# RL7005_IP_SVD register map
Vendor: Realtek
Registers are 32-bit, read-write, reset 0x0 unless marked. A register's access mark holds for its fields unless they carry their own. Offsets are from the block's base; [hi:lo] are bit positions; {n}, {i} and the like mark numbered series.

## PAGE1 (part 2 of 2)
Base 0x40000000
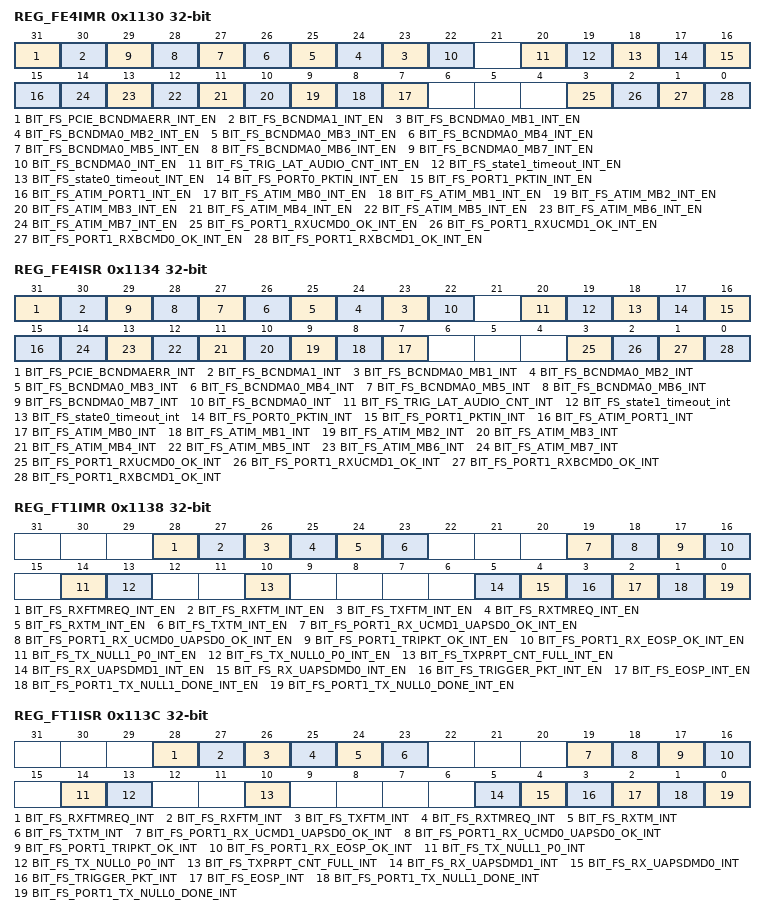
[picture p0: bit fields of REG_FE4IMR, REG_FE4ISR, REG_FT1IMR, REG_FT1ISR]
0x1130 REG_FE4IMR
  [31] BIT_FS_PCIE_BCNDMAERR_INT_EN — PCIE BCN DMA error interrupt
  [30] BIT_FS_BCNDMA1_INT_EN — When BCNDMA interval arrives before TBTT1, this interrupt informs MCU to prepare related beacon tasks.
  [n+22] BIT_FS_BCNDMA0_MB{n}_INT_EN (n=1..7) — When BCNDMA interval arrives before TBTT0_MB{n}, this interrupt informs MCU to prepare related beacon tasks.
  [22] BIT_FS_BCNDMA0_INT_EN — When BCNDMA interval arrives before TBTT0_MB0, this interrupt informs MCU to prepare related beacon tasks.
  [20] BIT_FS_TRIG_LAT_AUDIO_CNT_INT_EN — WLMAC trigger audio to latch counter periodically. Generate by P0/P1's TSFT.
  [19] BIT_FS_state1_timeout_INT_EN — when state0_timeout_timer is equal to r_state0_timeout_thres, which means state_0 is hang, hw will set this interrupt to inform sw
  [18] BIT_FS_state0_timeout_INT_EN — when state0_timeout_timer is equal to r_state0_timeout_thres, which means state_0 is hang, hw will set this interrupt to inform sw
  [17] BIT_FS_PORT0_PKTIN_INT_EN — port 0 packet assign to queue interrupt
  [16] BIT_FS_PORT1_PKTIN_INT_EN — port 1 packet assign to queue interrupt
  [15] BIT_FS_ATIM_PORT1_INT_EN — PORT1 ATIM end window interrupt .
  [n+7] BIT_FS_ATIM_MB{n}_INT_EN (n=0..7) — MBSSID{n} ATIM end window interrupt .
  [3] BIT_FS_PORT1_RXUCMD0_OK_INT_EN — port 1 rx unicast packet with more data = 0 ok interrupt
  [2] BIT_FS_PORT1_RXUCMD1_OK_INT_EN — port 1 rx unicast packet with more data = 1 ok interrupt
  [1] BIT_FS_PORT1_RXBCMD0_OK_INT_EN — port 1 rx broadcast packet with more data = 0 ok interrupt
  [0] BIT_FS_PORT1_RXBCMD1_OK_INT_EN — port 1 rx broadcast packet with more data = 1 ok interrupt
0x1134 REG_FE4ISR ro
  [31] BIT_FS_PCIE_BCNDMAERR_INT — PCIE BCN DMA error interrupt
  [30] BIT_FS_BCNDMA1_INT — When BCNDMA interval arrives before TBTT1, this interrupt informs MCU to prepare related beacon tasks.
  [n+22] BIT_FS_BCNDMA0_MB{n}_INT (n=1..7) — When BCNDMA interval arrives before TBTT0_MB{n}, this interrupt informs MCU to prepare related beacon tasks.
  [22] BIT_FS_BCNDMA0_INT — When BCNDMA interval arrives before TBTT0_MB0, this interrupt informs MCU to prepare related beacon tasks.
  [20] BIT_FS_TRIG_LAT_AUDIO_CNT_INT — WLMAC trigger audio to latch counter periodically. Generate by P0/P1's TSFT.
  [19] BIT_FS_state1_timeout_int — when state0_timeout_timer is equal to r_state0_timeout_thres, which means state_0 is hang, hw will set this interrupt to inform sw
  [18] BIT_FS_state0_timeout_int — when state0_timeout_timer is equal to r_state0_timeout_thres, which means state_0 is hang, hw will set this interrupt to inform sw
  [17] BIT_FS_PORT0_PKTIN_INT — port 0 packet assign to queue interrupt
  [16] BIT_FS_PORT1_PKTIN_INT — port 1 packet assign to queue interrupt
  [15] BIT_FS_ATIM_PORT1_INT — PORT1 ATIM end window interrupt .
  [n+7] BIT_FS_ATIM_MB{n}_INT (n=0..7) — MBSSID{n} ATIM end window interrupt .
  [3] BIT_FS_PORT1_RXUCMD0_OK_INT — port 1 rx unicast packet with more data = 0 ok interrupt
  [2] BIT_FS_PORT1_RXUCMD1_OK_INT — port 1 rx unicast packet with more data = 1 ok interrupt
  [1] BIT_FS_PORT1_RXBCMD0_OK_INT — port 1 rx broadcast packet with more data = 0 ok interrupt
  [0] BIT_FS_PORT1_RXBCMD1_OK_INT — port 1 rx broadcast packet with more data = 1 ok interrupt
0x1138 REG_FT1IMR
  [28] BIT_FS_RXFTMREQ_INT_EN — If BIT_RXFTMREQ_INT_EN =1. When HW receive FTMREQ packet, it will generate interrupt to firmware.
  [27] BIT_FS_RXFTM_INT_EN — If BIT_RXFTM_INT_EN =1. When HW receive FTM and transmit ACK frame successfully, the BB generate FTM report. It will generate interrupt to firmware.
  [26] BIT_FS_TXFTM_INT_EN — If BIT_TXFTM_INT_EN =1. When HW transmit FTM and receive ACK frame successfully, the BB generate FTM report. It will generate interrupt to firmware.
  [25] BIT_FS_RXTMREQ_INT_EN — If BIT_RXTMREQ_INT_EN =1. When HW receive TMREQ packet, it will generate interrupt to firmware.
  [24] BIT_FS_RXTM_INT_EN — If BIT_RXTM_INT_EN =1. When HW receive TM and transmit ACK frame successfully. It will generate interrupt to firmware.
  [23] BIT_FS_TXTM_INT_EN — If BIT_TXTM_INT_EN =1. When HW transmit TM and receive ACK frame successfully. It will generate interrupt to firmware.
  [19] BIT_FS_PORT1_RX_UCMD1_UAPSD0_OK_INT_EN — PORT1 rx unicast packet ok interrupt with more data =1 & UAPSD =0
  [18] BIT_FS_PORT1_RX_UCMD0_UAPSD0_OK_INT_EN — PORT1 rx unicast packet ok interrupt with more data =0 & UAPSD =0
  [17] BIT_FS_PORT1_TRIPKT_OK_INT_EN — PORT1 trigger packet assign to queue or release interrupt
  [16] BIT_FS_PORT1_RX_EOSP_OK_INT_EN — PORT1 RX packet with EOSP =1 ok interrupt
  [14] BIT_FS_TX_NULL1_P0_INT_EN — TX null 1 packet done interrupt
  [13] BIT_FS_TX_NULL0_P0_INT_EN — TX null 0 packet done interrupt
  [10] BIT_FS_TXPRPT_CNT_FULL_INT_EN — txrpt buffer full interrupt
  [5] BIT_FS_RX_UAPSDMD1_INT_EN — Setting this bit indicates Rx pkt is matched with one of below: 1.) QoS Unicast data frame with MD=1, UAPSD=0 2.) NonQoS Unicast data frame with MD=1
  [4] BIT_FS_RX_UAPSDMD0_INT_EN — Setting this bit indicates Rx pkt is matched with one of below: 1.) QoS Unicast data frame with MD=0, UAPSD=0 2.) NonQoS Unicast data frame with MD=0
  [3] BIT_FS_TRIGGER_PKT_INT_EN — tx TRIGGER_PKT interrupt
  [2] BIT_FS_EOSP_INT_EN — EOSP_INT interrupt mask
  [1] BIT_FS_PORT1_TX_NULL1_DONE_INT_EN — PORT1 TX NULL1 packet ok interrupt
  [0] BIT_FS_PORT1_TX_NULL0_DONE_INT_EN — PORT1 TX NULL0 packet ok interrupt
0x113C REG_FT1ISR ro
  [28] BIT_FS_RXFTMREQ_INT — If BIT_RXFTMREQ_INT_EN =1. When HW receive FTMREQ packet, it will generate interrupt to firmware.
  [27] BIT_FS_RXFTM_INT — If BIT_RXFTM_INT_EN =1. When HW receive FTM and transmit ACK frame successfully, the BB generate FTM report. It will generate interrupt to firmware.
  [26] BIT_FS_TXFTM_INT — If BIT_TXFTM_INT_EN =1. When HW transmit FTM and receive ACK frame successfully, the BB generate FTM report. It will generate interrupt to firmware.
  [25] BIT_FS_RXTMREQ_INT — If BIT_RXTMREQ_INT_EN =1. When HW receive TMREQ packet, it will generate interrupt to firmware.
  [24] BIT_FS_RXTM_INT — If BIT_RXTM_INT_EN =1. When HW receive TM and transmit ACK frame successfully. It will generate interrupt to firmware.
  [23] BIT_FS_TXTM_INT — If BIT_TXTM_INT_EN =1. When HW transmit TM and receive ACK frame successfully. It will generate interrupt to firmware.
  [19] BIT_FS_PORT1_RX_UCMD1_UAPSD0_OK_INT — PORT1 rx unicast packet ok interrupt with more data =1 & UAPSD =0
  [18] BIT_FS_PORT1_RX_UCMD0_UAPSD0_OK_INT — PORT1 rx unicast packet ok interrupt with more data =0 & UAPSD =0
  [17] BIT_FS_PORT1_TRIPKT_OK_INT — PORT1 trigger packet assign to queue or release interrupt
  [16] BIT_FS_PORT1_RX_EOSP_OK_INT — PORT1 RX packet with EOSP =1 ok interrupt
  [14] BIT_FS_TX_NULL1_P0_INT — TX null 1 packet done interrupt
  [13] BIT_FS_TX_NULL0_P0_INT — TX null 0 packet done interrupt
  [10] BIT_FS_TXPRPT_CNT_FULL_INT — txrpt buffer full interrupt
  [5] BIT_FS_RX_UAPSDMD1_INT — Setting this bit indicates Rx pkt is matched with one of below: 1.) QoS Unicast data frame with MD=1, UAPSD=0 2.) NonQoS Unicast data frame with MD=1
  [4] BIT_FS_RX_UAPSDMD0_INT — Setting this bit indicates Rx pkt is matched with one of below: 1.) QoS Unicast data frame with MD=0, UAPSD=0 2.) NonQoS Unicast data frame with MD=0
  [3] BIT_FS_TRIGGER_PKT_INT — tx TRIGGER_PKT interrupt
  [2] BIT_FS_EOSP_INT — EOSP_INT interrupt mask
  [1] BIT_FS_PORT1_TX_NULL1_DONE_INT — PORT1 TX NULL1 packet ok interrupt
  [0] BIT_FS_PORT1_TX_NULL0_DONE_INT — PORT1 TX NULL0 packet ok interrupt
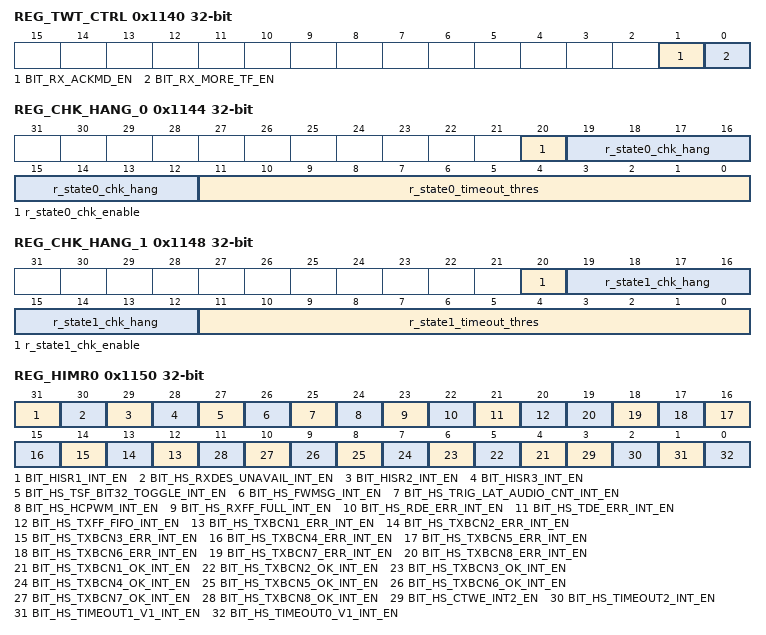
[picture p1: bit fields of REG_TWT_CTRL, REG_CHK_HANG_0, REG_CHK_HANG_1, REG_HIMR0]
0x1140 REG_TWT_CTRL
  [1] BIT_RX_ACKMD_EN — Enable ACK/BA/MU-BA frame more data interrupt
  [0] BIT_RX_MORE_TF_EN — Enable trigger frame more TF field interrupt
0x1144 REG_CHK_HANG_0
  [20] r_state0_chk_enable — function enable of check hang of state_0
  [19:12] r_state0_chk_hang — when r_state0_chk_enable is set, if state_0 is the value is equal to r_state0_chk_hang, starts state0_timeout_timer
  [11:0] r_state0_timeout_thres — timeout threshold of state0_timeout_timer, unit:us
0x1148 REG_CHK_HANG_1
  [20] r_state1_chk_enable — function enable of check hang of state_1
  [19:12] r_state1_chk_hang — when r_state1_chk_enable is set, if state_1 is the value is equal to r_state1_chk_hang, starts state1_timeout_timer
  [11:0] r_state1_timeout_thres — timeout threshold of state0_timeout_timer, unit:us
0x1150 REG_HIMR0
  [31] BIT_HISR1_INT_EN — HISR1 Indicator (HIISR1 andHIMR1 are true, this bit is set to 1)
  [30] BIT_HS_RXDES_UNAVAIL_INT_EN — Rx Descriptor Unavailable
  [29] BIT_HISR2_INT_EN — HISR2 Indicator (HIISR2 andHIMR2 are true, this bit is set to 1)
  [28] BIT_HISR3_INT_EN — HISR3 Indicator (HIISR3 andHIMR3 are true, this bit is set to 1)
  [27] BIT_HS_TSF_BIT32_TOGGLE_INT_EN — TSF Timer BIT32 toggle indication interrupt
  [26] BIT_HS_FWMSG_INT_EN — FW message interrupt,CPU to Host Command INT Status, Write 1 clear
  [25] BIT_HS_TRIG_LAT_AUDIO_CNT_INT_EN — WLMAC trigger audio to latch counter periodically. Generate by P0/P1's TSFT.
  [24] BIT_HS_HCPWM_INT_EN — CPWM interrupt,CPU power Mode exchange INT Status, Write 1 clear
  [23] BIT_HS_RXFF_FULL_INT_EN — Rxpktbuffer full interrupt
  [22] BIT_HS_RDE_ERR_INT_EN — Rxdma error interrupt
  [21] BIT_HS_TDE_ERR_INT_EN — Txdma error interrupt
  [20] BIT_HS_TXFF_FIFO_INT_EN — txpktbuffer full interrupt
  [n+11] BIT_HS_TXBCN{n}_ERR_INT_EN (n=1..8) — port0 BSSID{n-1} TX beacon error interrupt
  [n+3] BIT_HS_TXBCN{n}_OK_INT_EN (n=1..8) — port0 BSSID{n-1} TX beacon ok interrupt
  [3] BIT_HS_CTWE_INT2_EN — port2 CTWindow end interrupt for p2p.
  [2] BIT_HS_TIMEOUT2_INT_EN — tsf Timer2 interrupt
  [1] BIT_HS_TIMEOUT1_V1_INT_EN — tsf Timer1 interrupt
  [0] BIT_HS_TIMEOUT0_V1_INT_EN — tsf Timer0 interrupt
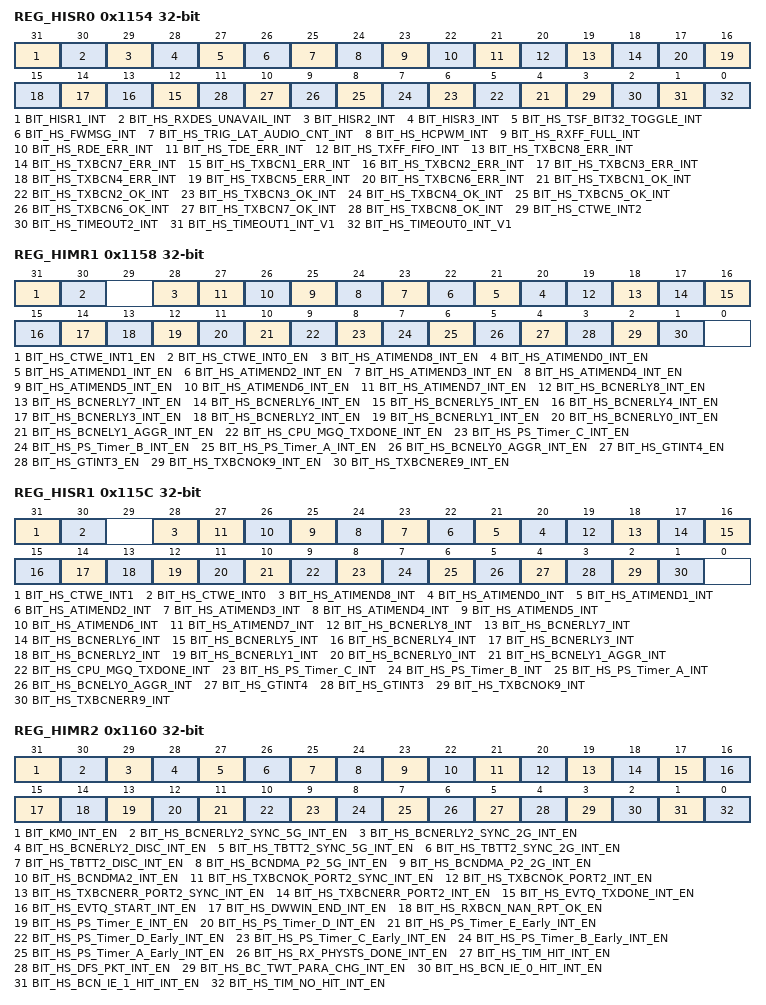
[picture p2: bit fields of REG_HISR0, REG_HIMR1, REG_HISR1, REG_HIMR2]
0x1154 REG_HISR0 ro
  [31] BIT_HISR1_INT — HISR1 Indicator (HIISR1 andHIMR1 are true, this bit is set to 1)
  [30] BIT_HS_RXDES_UNAVAIL_INT — Rx Descriptor Unavailable
  [29] BIT_HISR2_INT — HISR2 Indicator (HIISR2 andHIMR2 are true, this bit is set to 1)
  [28] BIT_HISR3_INT — HISR3 Indicator (HIISR3 andHIMR3 are true, this bit is set to 1)
  [27] BIT_HS_TSF_BIT32_TOGGLE_INT — TSF Timer BIT32 toggle indication interrupt
  [26] BIT_HS_FWMSG_INT — FW message interrupt,CPU to Host Command INT Status, Write 1 clear
  [25] BIT_HS_TRIG_LAT_AUDIO_CNT_INT — WLMAC trigger audio to latch counter periodically. Generate by P0/P1's TSFT.
  [24] BIT_HS_HCPWM_INT — CPWM interrupt,CPU power Mode exchange INT Status, Write 1 clear
  [23] BIT_HS_RXFF_FULL_INT — Rxpktbuffer full interrupt
  [22] BIT_HS_RDE_ERR_INT — Rxdma error interrupt
  [21] BIT_HS_TDE_ERR_INT — Txdma error interrupt
  [20] BIT_HS_TXFF_FIFO_INT — txpktbuffer full interrupt
  [19] BIT_HS_TXBCN8_ERR_INT — port0 BSSID7 TRX beacon error interrupt (ap is txbcn, sta is rxbcn)
  [18] BIT_HS_TXBCN7_ERR_INT — port0 BSSID6 TRX beacon error interrupt (ap is txbcn, sta is rxbcn)
  [n+11] BIT_HS_TXBCN{n}_ERR_INT (n=1..6) — port0 BSSID{n-1} TRX beacon error interrupt(ap is txbcn, sta is rxbcn)
  [n+3] BIT_HS_TXBCN{n}_OK_INT (n=1..8) — port0 BSSID{n-1} TRX beacon ok interrupt(ap is txbcn, sta is rxbcn)
  [3] BIT_HS_CTWE_INT2 — port2 CTWindow end interrupt for p2p.
  [2] BIT_HS_TIMEOUT2_INT — tsf Timer2 interrupt
  [1] BIT_HS_TIMEOUT1_INT_V1 — tsf Timer1 interrupt
  [0] BIT_HS_TIMEOUT0_INT_V1 — tsf Timer0 interrupt
0x1158 REG_HIMR1
  [31] BIT_HS_CTWE_INT1_EN — Client1 traffic window end interrupt for P2P
  [30] BIT_HS_CTWE_INT0_EN — Client0 traffic window end interrupt for P2P
  [28] BIT_HS_ATIMEND8_INT_EN — port1 atimend interrupt
  [n+20] BIT_HS_ATIMEND{n}_INT_EN (n=0..7) — port0 BSSID{n} atimend interrupt
  [19] BIT_HS_BCNERLY8_INT_EN — port1 beacon early interrupt
  [18] BIT_HS_BCNERLY7_INT_EN — port0 BSSID7 beacon early interrupt , only valid under MBSSID mode
  [17] BIT_HS_BCNERLY6_INT_EN — port0 BSSID6 beacon early interrupt , only valid under MBSSID mode
  [16] BIT_HS_BCNERLY5_INT_EN — port0 BSSID5 beacon early interrupt , only valid under MBSSID mode
  [15] BIT_HS_BCNERLY4_INT_EN — port0 BSSID4 beacon early interrupt, only valid under MBSSID mode
  [14] BIT_HS_BCNERLY3_INT_EN — port0 BSSID3 beacon early interrupt , only valid under MBSSID mode
  [13] BIT_HS_BCNERLY2_INT_EN — port0 BSSID2 beacon early interrupt, only valid under MBSSID mode
  [12] BIT_HS_BCNERLY1_INT_EN — port0 BSSID1 beacon early interrupt , only valid under MBSSID mode
  [11] BIT_HS_BCNERLY0_INT_EN — This interrupt is issued at the time set by DRVERLYINT register before TBTT time for port 0 root bssid
  [10] BIT_HS_BCNELY1_AGGR_INT_EN — port 1 Beacon early aggregation interrupt
  [9] BIT_HS_CPU_MGQ_TXDONE_INT_EN — CPU_MQG_TXDONE ineterrupt source when HW TX CPUMGQ packet success, it issue interrupt to host
  [8] BIT_HS_PS_Timer_C_INT_EN — PS_Timer_C interrupt source When the lower 4 bytes of TSF(that select by reg 0x1510[18:16]) matches the content of this register, the PS_Timer_C_INT interrupt is issued
  [7] BIT_HS_PS_Timer_B_INT_EN — PS_Timer_B interrupt source When the lower 4 bytes of TSF(that select by reg 0x1510[10:8]) matches the content of this register, the PS_Timer_B_INT interrupt is issued
  [6] BIT_HS_PS_Timer_A_INT_EN — PS_Timer_A interrupt source When the lower 4 bytes of TSF(that select by reg 0x1510[2:0]) matches the content of this register, the PS_Timer_A_INT interrupt is issued
  [5] BIT_HS_BCNELY0_AGGR_INT_EN — port 0 Beacon early aggregation interrupt
  [4] BIT_HS_GTINT4_EN — When GTIMER4 expires, this bit is set to 1
  [3] BIT_HS_GTINT3_EN — When GTIMER3 expires, this bit is set to 1
  [2] BIT_HS_TXBCNOK9_INT_EN — PORT1 TRX beacon OK interrupt (ap is txbcn, sta is rxbcn)
  [1] BIT_HS_TXBCNERE9_INT_EN — PORT1 TRX beacon Error interrupt (ap is txbcn, sta is rxbcn)
0x115C REG_HISR1 ro
  [31] BIT_HS_CTWE_INT1 — port1 CTWindow end interrupt for p2p.
  [30] BIT_HS_CTWE_INT0 — port0 CTWindow end interrupt for p2p.
  [28] BIT_HS_ATIMEND8_INT — port1 atimend interrupt
  [n+20] BIT_HS_ATIMEND{n}_INT (n=0..7) — port0 BSSID{n} atimend interrupt
  [19] BIT_HS_BCNERLY8_INT — port1 beacon early interrupt
  [18] BIT_HS_BCNERLY7_INT — port0 BSSID7 beacon early interrupt , only valid under MBSSID mode
  [17] BIT_HS_BCNERLY6_INT — port0 BSSID6 beacon early interrupt , only valid under MBSSID mode
  [16] BIT_HS_BCNERLY5_INT — port0 BSSID5 beacon early interrupt , only valid under MBSSID mode
  [15] BIT_HS_BCNERLY4_INT — port0 BSSID4 beacon early interrupt, only valid under MBSSID mode
  [14] BIT_HS_BCNERLY3_INT — port0 BSSID3 beacon early interrupt , only valid under MBSSID mode
  [13] BIT_HS_BCNERLY2_INT — port0 BSSID2 beacon early interrupt, only valid under MBSSID mode
  [12] BIT_HS_BCNERLY1_INT — port0 BSSID1 beacon early interrupt , only valid under MBSSID mode
  [11] BIT_HS_BCNERLY0_INT — This interrupt is issued at the time set by DRVERLYINT register before TBTT time for port 0 root bssid
  [10] BIT_HS_BCNELY1_AGGR_INT — port 1 Beacon early aggregation interrupt
  [9] BIT_HS_CPU_MGQ_TXDONE_INT — CPU_MQG_TXDONE ineterrupt source when HW TX CPUMGQ packet success, it issue interrupt to host
  [8] BIT_HS_PS_Timer_C_INT — PS_Timer_C interrupt source When the lower 4 bytes of TSF(that select by reg 0x1510[18:16]) matches the content of this register, the PS_Timer_C_INT interrupt is issued
  [7] BIT_HS_PS_Timer_B_INT — PS_Timer_B interrupt source When the lower 4 bytes of TSF(that select by reg 0x1510[10:8]) matches the content of this register, the PS_Timer_B_INT interrupt is issued
  [6] BIT_HS_PS_Timer_A_INT — PS_Timer_A interrupt source When the lower 4 bytes of TSF(that select by reg 0x1510[2:0]) matches the content of this register, the PS_Timer_A_INT interrupt is issued
  [5] BIT_HS_BCNELY0_AGGR_INT — port 0 Beacon early aggregation interrupt
  [4] BIT_HS_GTINT4 — When GTIMER4 expires, this bit is set to 1
  [3] BIT_HS_GTINT3 — When GTIMER3 expires, this bit is set to 1
  [2] BIT_HS_TXBCNOK9_INT — PORT1 TX beacon OK interrupt
  [1] BIT_HS_TXBCNERR9_INT — PORT1 TX beacon Error interrupt
0x1160 REG_HIMR2
  [31] BIT_KM0_INT_EN — The gathering of interrupts of KM0
  [30] BIT_HS_BCNERLY2_SYNC_5G_INT_EN — This interrupt is issued at the time set by DRVERLYINT register before TBTT2 SYNC 5G time.
  [29] BIT_HS_BCNERLY2_SYNC_2G_INT_EN — This interrupt is issued at the time set by DRVERLYINT register before TBTT2 SYNC 2.4G time.
  [28] BIT_HS_BCNERLY2_DISC_INT_EN — This interrupt is issued at the time set by DRVERLYINT register before TBTT2 DISC time.
  [27] BIT_HS_TBTT2_SYNC_5G_INT_EN — the interrupt from the exact TBTT time for P2 SYNC_5G.
  [26] BIT_HS_TBTT2_SYNC_2G_INT_EN — the interrupt from the exact TBTT time for P2 SYNC_2G.
  [25] BIT_HS_TBTT2_DISC_INT_EN — the interrupt from the exact TBTT time for P2.
  [24] BIT_HS_BCNDMA_P2_5G_INT_EN — When BCNDMA interval arrives before TBTT2_5G_SYNC, this interrupt informs MCU to prepare related beacon tasks.
  [23] BIT_HS_BCNDMA_P2_2G_INT_EN — When BCNDMA interval arrives before TBTT2_2G_SYNC, this interrupt informs MCU to prepare related beacon tasks.
  [22] BIT_HS_BCNDMA2_INT_EN — When BCNDMA interval arrives before TBTT2_DISC, this interrupt informs MCU to prepare related beacon tasks.
  [21] BIT_HS_TXBCNOK_PORT2_SYNC_INT_EN — PORT2 TX SYNC beacon OK interrupt
  [20] BIT_HS_TXBCNOK_PORT2_INT_EN — PORT2 TX DISC beacon OK interrupt
  [19] BIT_HS_TXBCNERR_PORT2_SYNC_INT_EN — PORT2 TX SYNC beacon Error interrupt
  [18] BIT_HS_TXBCNERR_PORT2_INT_EN — PORT2 TX DISC beacon Error interrupt
  [17] BIT_HS_EVTQ_TXDONE_INT_EN — event queue done interrupt for NAN
  [16] BIT_HS_EVTQ_START_INT_EN — event queue start interrupt for NAN
  [15] BIT_HS_DWWIN_END_INT_EN — discovery window end interrupt for NAN
  [14] BIT_HS_RXBCN_NAN_RPT_OK_EN — port2 rxbcn rpt and write to txrptbuf ok
  [13] BIT_HS_PS_Timer_E_INT_EN — PS_Timer_E interrupt When the TSF(that select by reg 0x1520[13:12]) matches the content of this register, the PS_Timer_E_INT interrupt is issued
  [12] BIT_HS_PS_Timer_D_INT_EN — PS_Timer_D interrupt When the lower 4 bytes of TSF(that select by reg 0x1520[17:16]) matches the content of this register, the PS_Timer_D_INT interrupt is issued
  [11] BIT_HS_PS_Timer_E_Early_INT_EN — This interrupt is issued at the time set by PS_Timer_E_Early register before PS_Timer_E time.
  [10] BIT_HS_PS_Timer_D_Early_INT_EN — This interrupt is issued at the time set by PS_Timer_D_Early register before PS_Timer_D time.
  [9] BIT_HS_PS_Timer_C_Early_INT_EN — This interrupt is issued at the time set by PS_Timer_C_Early register before PS_Timer_C time.
  [8] BIT_HS_PS_Timer_B_Early_INT_EN — This interrupt is issued at the time set by PS_Timer_B_Early register before PS_Timer_B time.
  [7] BIT_HS_PS_Timer_A_Early_INT_EN — This interrupt is issued at the time set by PS_Timer_A_Early register before PS_Timer_A time.
  [6] BIT_HS_RX_PHYSTS_DONE_INT_EN — indicate physts is successfully write into physts_mem
  [5] BIT_HS_TIM_HIT_INT_EN — when my aid or aid is 0 (0x16DC[8]) or my bssid is in tim element,generate this interrupt
  [4] BIT_HS_DFS_PKT_INT_EN — enable interrupt when receiving dfs pkt and about to reach threshold of given pkt number or timeout
  [3] BIT_HS_BC_TWT_PARA_CHG_INT_EN — RX broadcast twt with parameter changing,notify fw to read twt report
  [2] BIT_HS_BCN_IE_0_HIT_INT_EN — rx bcn with ie0 hit
  [1] BIT_HS_BCN_IE_1_HIT_INT_EN — rx bcn with ie1 hit
  [0] BIT_HS_TIM_NO_HIT_INT_EN — when no my aid or aid is 0(0x16DC[8]) or my bssid is not in tim element(0x16DB[31]),generate this interrupt
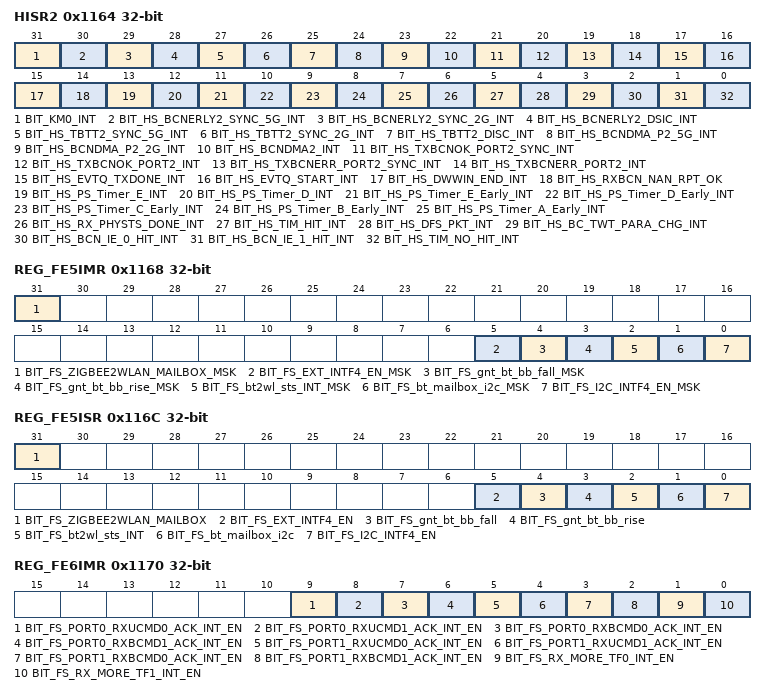
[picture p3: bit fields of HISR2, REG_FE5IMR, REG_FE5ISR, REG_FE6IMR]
0x1164 HISR2 ro
  [31] BIT_KM0_INT — The gathering of interrupts of KM0
  [30] BIT_HS_BCNERLY2_SYNC_5G_INT — This interrupt is issued at the time set by DRVERLYINT register before TBTT2 SYNC 5G time.
  [29] BIT_HS_BCNERLY2_SYNC_2G_INT — This interrupt is issued at the time set by DRVERLYINT register before TBTT2 SYNC 2.4G time.
  [28] BIT_HS_BCNERLY2_DSIC_INT — This interrupt is issued at the time set by DRVERLYINT register before TBTT2 DISC time.
  [27] BIT_HS_TBTT2_SYNC_5G_INT — the interrupt from the exact TBTT time for P2 SYNC_5G.
  [26] BIT_HS_TBTT2_SYNC_2G_INT — the interrupt from the exact TBTT time for P2 SYNC_2G.
  [25] BIT_HS_TBTT2_DISC_INT — the interrupt from the exact TBTT time for P2.
  [24] BIT_HS_BCNDMA_P2_5G_INT — When BCNDMA interval arrives before TBTT2_5G_SYNC, this interrupt informs MCU to prepare related beacon tasks.
  [23] BIT_HS_BCNDMA_P2_2G_INT — When BCNDMA interval arrives before TBTT2_2G_SYNC, this interrupt informs MCU to prepare related beacon tasks.
  [22] BIT_HS_BCNDMA2_INT — When BCNDMA interval arrives before TBTT2_DISC, this interrupt informs MCU to prepare related beacon tasks.
  [21] BIT_HS_TXBCNOK_PORT2_SYNC_INT — PORT2 TX SYNC beacon OK interrupt
  [20] BIT_HS_TXBCNOK_PORT2_INT — PORT2 TX DISC beacon OK interrupt
  [19] BIT_HS_TXBCNERR_PORT2_SYNC_INT — PORT2 TX SYNC beacon Error interrupt
  [18] BIT_HS_TXBCNERR_PORT2_INT — PORT2 TX DISC beacon Error interrupt
  [17] BIT_HS_EVTQ_TXDONE_INT — event queue done interrupt for NAN
  [16] BIT_HS_EVTQ_START_INT — event queue start interrupt for NAN
  [15] BIT_HS_DWWIN_END_INT — discovery window end interrupt for NAN
  [14] BIT_HS_RXBCN_NAN_RPT_OK — port2 rxbcn rpt and write to txrptbuf ok
  [13] BIT_HS_PS_Timer_E_INT — PS_Timer_E interrupt When the TSF(that select by reg 0x1520[13:12]) matches the content of this register, the PS_Timer_E_INT interrupt is issued
  [12] BIT_HS_PS_Timer_D_INT — PS_Timer_D interrupt When the lower 4 bytes of TSF(that select by reg 0x1520[17:16]) matches the content of this register, the PS_Timer_D_INT interrupt is issued
  [11] BIT_HS_PS_Timer_E_Early_INT — This interrupt is issued at the time set by PS_Timer_E_Early register before PS_Timer_E time.
  [10] BIT_HS_PS_Timer_D_Early_INT — This interrupt is issued at the time set by PS_Timer_D_Early register before PS_Timer_D time.
  [9] BIT_HS_PS_Timer_C_Early_INT — This interrupt is issued at the time set by PS_Timer_C_Early register before PS_Timer_C time.
  [8] BIT_HS_PS_Timer_B_Early_INT — This interrupt is issued at the time set by PS_Timer_B_Early register before PS_Timer_B time.
  [7] BIT_HS_PS_Timer_A_Early_INT — This interrupt is issued at the time set by PS_Timer_A_Early register before PS_Timer_A time.
  [6] BIT_HS_RX_PHYSTS_DONE_INT — indicate physts is successfully write into physts_mem
  [5] BIT_HS_TIM_HIT_INT — when my aid or aid is 0 (0x16DC[8]) or my bssid is in tim element,generate this interrupt
  [4] BIT_HS_DFS_PKT_INT — enable interrupt when receiving dfs pkt and about to reach threshold of given pkt number or timeout
  [3] BIT_HS_BC_TWT_PARA_CHG_INT — RX broadcast twt with parameter changing,notify fw to read twt report
  [2] BIT_HS_BCN_IE_0_HIT_INT — rx bcn with ie0 hit
  [1] BIT_HS_BCN_IE_1_HIT_INT — rx bcn with ie1 hit
  [0] BIT_HS_TIM_NO_HIT_INT — when no my aid or aid is 0(0x16DC[8]) or my bssid is not in tim element(0x16DB[31]),generate this interrupt
0x1168 REG_FE5IMR
  [31] BIT_FS_ZIGBEE2WLAN_MAILBOX_MSK — Mailbox INT from ZIGBEE CPU
  [5] BIT_FS_EXT_INTF4_EN_MSK — bt mailbox int,mailbox_outempty_int| mailbox_in_rdy_int from internal BT
  [4] BIT_FS_gnt_bt_bb_fall_MSK — gnt_bt falling edge
  [3] BIT_FS_gnt_bt_bb_rise_MSK — gnt bt rising edge
  [2] BIT_FS_bt2wl_sts_INT_MSK — Mailbox INT from internal BT
  [1] BIT_FS_bt_mailbox_i2c_MSK — 1_wire Mailbox INT from internal BT
  [0] BIT_FS_I2C_INTF4_EN_MSK — bt mailbox int,mailbox_outempty_int| mailbox_in_rdy_int form EXT BT,no use,tie 0
0x116C REG_FE5ISR access per field
  [31] BIT_FS_ZIGBEE2WLAN_MAILBOX ro — Mailbox INT from ZIGBEE CPU
  [5] BIT_FS_EXT_INTF4_EN ro — bt mailbox int,mailbox_outempty_int| mailbox_in_rdy_int from internal BT
  [4] BIT_FS_gnt_bt_bb_fall ro — gnt_bt falling edge
  [3] BIT_FS_gnt_bt_bb_rise ro — gnt bt rising edge
  [2] BIT_FS_bt2wl_sts_INT ro — Mailbox INT from internal BT
  [1] BIT_FS_bt_mailbox_i2c ro — 1_wire Mailbox INT from internal BT
  [0] BIT_FS_I2C_INTF4_EN ro — bt mailbox int,mailbox_outempty_int| mailbox_in_rdy_int form EXT BT,no use,tie 0
0x1170 REG_FE6IMR access per field
  [9] BIT_FS_PORT0_RXUCMD0_ACK_INT_EN rw — port 0 rx unicast ACK/BA/MBA with more data = 0 ok interrupt
  [8] BIT_FS_PORT0_RXUCMD1_ACK_INT_EN rw — port 0 rx unicast ACK/BA/MBA with more data = 1 ok interrupt
  [7] BIT_FS_PORT0_RXBCMD0_ACK_INT_EN rw — port 0 rx broadcast ACK/BA/MBA with more data = 0 ok interrupt
  [6] BIT_FS_PORT0_RXBCMD1_ACK_INT_EN rw — port 0 rx broadcast ACK/BA/MBA with more data = 1 ok interrupt
  [5] BIT_FS_PORT1_RXUCMD0_ACK_INT_EN rw — port 1 rx unicast ACK/BA/MBA with more data = 0 ok interrupt
  [4] BIT_FS_PORT1_RXUCMD1_ACK_INT_EN rw — port 1 rx unicast ACK/BA/MBA with more data = 1 ok interrupt
  [3] BIT_FS_PORT1_RXBCMD0_ACK_INT_EN rw — port 1 rx broadcast ACK/BA/MBA with more data = 0 ok interrupt
  [2] BIT_FS_PORT1_RXBCMD1_ACK_INT_EN rw — port 1 rx broadcast ACK/BA/MBA with more data = 1 ok interrupt
  [1] BIT_FS_RX_MORE_TF0_INT_EN rw — interrupt source from trigger frame with more TF field = 0 not addressed to us
  [0] BIT_FS_RX_MORE_TF1_INT_EN rw — Interrupt source from receiving trigger frame with more TF field = 1 not addressed to us
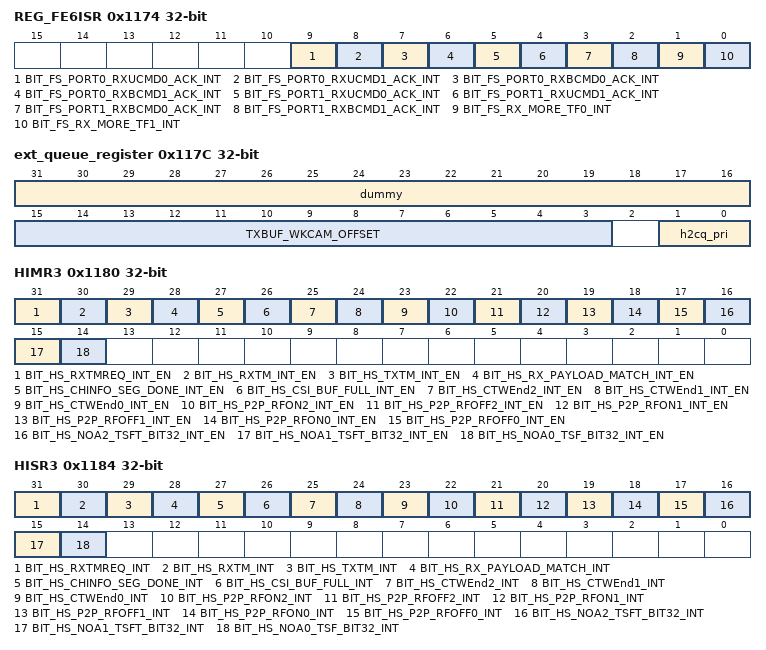
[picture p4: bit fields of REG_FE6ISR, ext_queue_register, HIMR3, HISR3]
0x1174 REG_FE6ISR access per field
  [9] BIT_FS_PORT0_RXUCMD0_ACK_INT ro — port 0 rx unicast ACK/BA/MBA with more data = 0 ok interrupt
  [8] BIT_FS_PORT0_RXUCMD1_ACK_INT ro — port 0 rx unicast ACK/BA/MBA with more data = 1 ok interrupt
  [7] BIT_FS_PORT0_RXBCMD0_ACK_INT ro — port 0 rx broadcast ACK/BA/MBA with more data = 0 ok interrupt
  [6] BIT_FS_PORT0_RXBCMD1_ACK_INT ro — port 0 rx broadcast ACK/BA/MBA with more data = 1 ok interrupt
  [5] BIT_FS_PORT1_RXUCMD0_ACK_INT ro — port 1 rx unicast ACK/BA/MBA with more data = 0 ok interrupt
  [4] BIT_FS_PORT1_RXUCMD1_ACK_INT ro — port 1 rx unicast ACK/BA/MBA with more data = 1 ok interrupt
  [3] BIT_FS_PORT1_RXBCMD0_ACK_INT ro — port 1 rx broadcast ACK/BA/MBA with more data = 0 ok interrupt
  [2] BIT_FS_PORT1_RXBCMD1_ACK_INT ro — port 1 rx broadcast ACK/BA/MBA with more data = 1 ok interrupt
  [1] BIT_FS_RX_MORE_TF0_INT ro — interrupt source from trigger frame with more TF field = 0 not addressed to us
  [0] BIT_FS_RX_MORE_TF1_INT ro — Interrupt source from receiving trigger frame with more TF field = 1 not addressed to us
0x117C ext_queue_register
  [31:16] dummy
  [15:3] TXBUF_WKCAM_OFFSET — the offset of WOL pattern stored in txpktbuffer, unit is 8byte
  [1:0] h2cq_pri
0x1180 HIMR3
  [31] BIT_HS_RXTMREQ_INT_EN — If BIT_RXTMREQ_INT_EN =1. When HW receive TMREQ packet, it will generate interrupt to firmware.
  [30] BIT_HS_RXTM_INT_EN — If BIT_RXTM_INT_EN =1. When HW receive TM and transmit ACK frame successfully. It will generate interrupt to firmware.
  [29] BIT_HS_TXTM_INT_EN — If BIT_TXTM_INT_EN =1. When HW transmit TM and receive ACK frame successfully. It will generate interrupt to firmware.
  [28] BIT_HS_RX_PAYLOAD_MATCH_INT_EN — indicate rx payload content match
  [27] BIT_HS_CHINFO_SEG_DONE_INT_EN — indicate one channel info segment is received ok
  [26] BIT_HS_CSI_BUF_FULL_INT_EN — indicate channel info rxcsibuffer is full
  [25] BIT_HS_CTWEnd2_INT_EN — CTWindow End NOA2 interrupt.
  [24] BIT_HS_CTWEnd1_INT_EN — CTWindow End NOA1 interrupt.
  [23] BIT_HS_CTWEnd0_INT_EN — CTWindow End NOA0 interrupt.
  [22] BIT_HS_P2P_RFON2_INT_EN — P2P NoA RF on time indication 2 interrupt
  [21] BIT_HS_P2P_RFOFF2_INT_EN — P2P NoA RF off time indication 2 interrupt
  [20] BIT_HS_P2P_RFON1_INT_EN — P2P NoA RF on time indication 1 interrupt
  [19] BIT_HS_P2P_RFOFF1_INT_EN — P2P NoA RF off time indication 1 interrupt
  [18] BIT_HS_P2P_RFON0_INT_EN — P2P NoA RF on time indication 0 interrupt
  [17] BIT_HS_P2P_RFOFF0_INT_EN — P2P NoA RF off time indication 0 interrupt
  [16] BIT_HS_NOA2_TSFT_BIT32_INT_EN — NOA unit2 TSFT bit 32 toggle interrupt
  [15] BIT_HS_NOA1_TSFT_BIT32_INT_EN — NOA unit1 TSFT bit 32 toggle interrupt
  [14] BIT_HS_NOA0_TSF_BIT32_INT_EN — NOA unit0 TSFT bit 32 toggle interrupt
0x1184 HISR3 ro
  [31] BIT_HS_RXTMREQ_INT — If BIT_RXTMREQ_INT_EN =1. When HW receive TMREQ packet, it will generate interrupt to firmware.
  [30] BIT_HS_RXTM_INT — If BIT_RXTM_INT_EN =1. When HW receive TM and transmit ACK frame successfully. It will generate interrupt to firmware.
  [29] BIT_HS_TXTM_INT — If BIT_TXTM_INT_EN =1. When HW transmit TM and receive ACK frame successfully. It will generate interrupt to firmware.
  [28] BIT_HS_RX_PAYLOAD_MATCH_INT — indicate rx payload content match
  [27] BIT_HS_CHINFO_SEG_DONE_INT — indicate one channel info segment is received ok
  [26] BIT_HS_CSI_BUF_FULL_INT — indicate channel info rxcsibuffer is full
  [25] BIT_HS_CTWEnd2_INT — CTWindow End NOA2 interrupt.
  [24] BIT_HS_CTWEnd1_INT — CTWindow End NOA1 interrupt.
  [23] BIT_HS_CTWEnd0_INT — CTWindow End NOA0 interrupt.
  [22] BIT_HS_P2P_RFON2_INT — P2P NoA RF on time indication 2 interrupt
  [21] BIT_HS_P2P_RFOFF2_INT — P2P NoA RF off time indication 2 interrupt
  [20] BIT_HS_P2P_RFON1_INT — P2P NoA RF on time indication 1 interrupt
  [19] BIT_HS_P2P_RFOFF1_INT — P2P NoA RF off time indication 1 interrupt
  [18] BIT_HS_P2P_RFON0_INT — P2P NoA RF on time indication 0 interrupt
  [17] BIT_HS_P2P_RFOFF0_INT — P2P NoA RF off time indication 0 interrupt
  [16] BIT_HS_NOA2_TSFT_BIT32_INT — NOA unit2 TSFT bit 32 toggle interrupt
  [15] BIT_HS_NOA1_TSFT_BIT32_INT — NOA unit1 TSFT bit 32 toggle interrupt
  [14] BIT_HS_NOA0_TSF_BIT32_INT — NOA unit0 TSFT bit 32 toggle interrupt
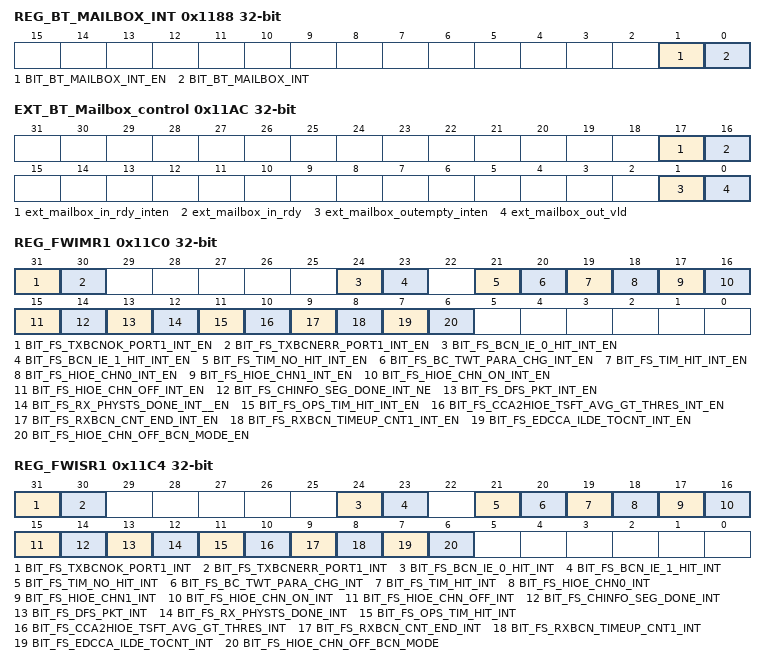
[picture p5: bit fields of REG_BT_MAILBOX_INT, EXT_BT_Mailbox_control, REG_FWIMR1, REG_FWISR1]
0x1188 REG_BT_MAILBOX_INT access per field
  [1] BIT_BT_MAILBOX_INT_EN rw — bt2wl and wl2bt mailbox interrupt mask
  [0] BIT_BT_MAILBOX_INT ro — bt2wl and wl2bt mailbox interrupt
0x11A4 EXT_BT_MAILBOX_OUT_LOW
  [31:0] ext_mailbox_data_51to81_l
0x11A8 EXT_BT_MAILBOX_OUT_HIGH
  [31:0] ext_mailbox_data_51to81_h
0x11AC EXT_BT_Mailbox_control access per field
  [17] ext_mailbox_in_rdy_inten rw — Mailbox IN ready interrupt enable
  [16] ext_mailbox_in_rdy ro — Mailbox ready BT2Wifi
  [1] ext_mailbox_outempty_inten rw — Mailbox OUT empty interrupt enable
  [0] ext_mailbox_out_vld ro — Mailbox ACK Wifi2BT
0x11B0 EXT_BT_MAILBOX_IN_LOW ro
  [31:0] ext_mailbox_data_81to51_l
0x11B4 EXT_BT_MAILBOX_IN_HIGH ro
  [31:0] ext_mailbox_data_81_to51_h
0x11C0 REG_FWIMR1
  [31] BIT_FS_TXBCNOK_PORT1_INT_EN — ENABLE PORT1 TX beacon OK interrupt
  [30] BIT_FS_TXBCNERR_PORT1_INT_EN — ENABLE PORT1 TX beacon Error interrupt
  [24] BIT_FS_BCN_IE_0_HIT_INT_EN — rx bcn with ie0 hit
  [23] BIT_FS_BCN_IE_1_HIT_INT_EN — rx bcn with ie1 hit
  [21] BIT_FS_TIM_NO_HIT_INT_EN — when no my aid or aid is 0(0x16DC[8]) or my bssid is not in tim element(0x16DB[31]),generate this interrupt
  [20] BIT_FS_BC_TWT_PARA_CHG_INT_EN — RX broadcast twt with parameter changing,notify fw to read twt report
  [19] BIT_FS_TIM_HIT_INT_EN — when my aid or aid is 0 (0x16DC[8]) or my bssid is in tim element,generate this interrupt
  [18] BIT_FS_HIOE_CHN0_INT_EN — hioe_chn0 done interrupt
  [17] BIT_FS_HIOE_CHN1_INT_EN — hioe_chn1 done interrupt
  [16] BIT_FS_HIOE_CHN_ON_INT_EN — hioe_chn_on done interrupt
  [15] BIT_FS_HIOE_CHN_OFF_INT_EN — hioe_chn_off done interrupt
  [14] BIT_FS_CHINFO_SEG_DONE_INT_NE — indicate one channel info segment is received ok
  [13] BIT_FS_DFS_PKT_INT_EN — enable interrupt when receiving dfs pkt and about to reach threshold of given pkt number or timeout
  [12] BIT_FS_RX_PHYSTS_DONE_INT__EN — indicate physts is successfully write into physts_mem
  [11] BIT_FS_OPS_TIM_HIT_INT_EN — when my aid or my bssid is in tim frame/ops frame,generate this interrupt
  [10] BIT_FS_CCA2HIOE_TSFT_AVG_GT_THRES_INT_EN — If the BIT_TSFT_AVG_VALUE exceeds the BIT_TSFT_AVG_THRES several times in a row, and the number exceeds the BIT_TSFT_AVG_GT_THRES_CNT_MAX, generate an interrupt.
  [9] BIT_FS_RXBCN_CNT_END_INT_EN — Generate the interrupt when RXBCN period cnt == 2^ BIT_RXBCN_CNT_PRD
  [8] BIT_FS_RXBCN_TIMEUP_CNT1_INT_EN — the interrupt is issued when RX beacon frame timeout occurs specified times in port0.specified by 0x10A[22:16](only enabled when 0x17C[26]=1)
  [7] BIT_FS_EDCCA_ILDE_TOCNT_INT_EN — when edcca is low after tbtt, start timer,when timeout for few times(0x180~0x188),set this interrupt
  [6] BIT_FS_HIOE_CHN_OFF_BCN_MODE_EN — hioe_chn_bcn_mode done interrupt
0x11C4 REG_FWISR1 ro
  [31] BIT_FS_TXBCNOK_PORT1_INT — PORT1 TX beacon OK interrupt
  [30] BIT_FS_TXBCNERR_PORT1_INT — PORT1 TX beacon Error interrupt
  [24] BIT_FS_BCN_IE_0_HIT_INT — rx bcn with ie0 hit
  [23] BIT_FS_BCN_IE_1_HIT_INT — rx bcn with ie1 hit
  [21] BIT_FS_TIM_NO_HIT_INT — when no my aid or aid is 0(0x16DC[8]) or my bssid is not in tim element(0x16DB[31]),generate this interrupt
  [20] BIT_FS_BC_TWT_PARA_CHG_INT — RX broadcast twt with parameter changing,notify fw to read twt report
  [19] BIT_FS_TIM_HIT_INT — when my aid or aid is 0 (0x16DC[8]) or my bssid is in tim element,generate this interrupt
  [18] BIT_FS_HIOE_CHN0_INT — hioe_chn0 done interrupt
  [17] BIT_FS_HIOE_CHN1_INT — hioe_chn1 done interrupt
  [16] BIT_FS_HIOE_CHN_ON_INT — hioe_chn_on done interrupt
  [15] BIT_FS_HIOE_CHN_OFF_INT — hioe_chn_off done interrupt
  [14] BIT_FS_CHINFO_SEG_DONE_INT — indicate one channel info segment is received ok
  [13] BIT_FS_DFS_PKT_INT — enable interrupt when receiving dfs pkt and about to reach threshold of given pkt number or timeout
  [12] BIT_FS_RX_PHYSTS_DONE_INT — indicate physts is successfully write into physts_mem
  [11] BIT_FS_OPS_TIM_HIT_INT — when my aid or my bssid is in tim frame/ops frame,generate this interrupt
  [10] BIT_FS_CCA2HIOE_TSFT_AVG_GT_THRES_INT — If the BIT_TSFT_AVG_VALUE exceeds the BIT_TSFT_AVG_THRES several times in a row, and the number exceeds the BIT_TSFT_AVG_GT_THRES_CNT_MAX, generate an interrupt.
  [9] BIT_FS_RXBCN_CNT_END_INT — Generate the interrupt when RXBCN period cnt == 2^ BIT_RXBCN_CNT_PRD
  [8] BIT_FS_RXBCN_TIMEUP_CNT1_INT — the interrupt is issued when RX beacon frame timeout occurs specified times in port0.specified by 0x10A[22:16](only enabled when 0x17C[26]=1)
  [7] BIT_FS_EDCCA_ILDE_TOCNT_INT — when edcca is low after tbtt, start timer,when timeout for few times(0x180~0x188),set this interrupt
  [6] BIT_FS_HIOE_CHN_OFF_BCN_MODE — hioe_chn_bcn_mode done interrupt
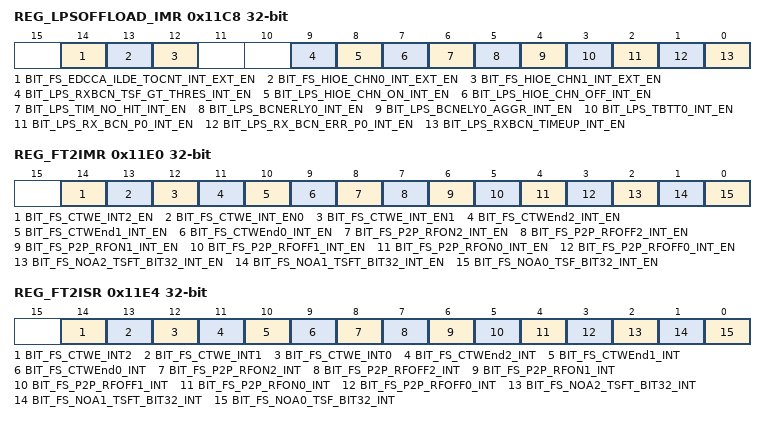
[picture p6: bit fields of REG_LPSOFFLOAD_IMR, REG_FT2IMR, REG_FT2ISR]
0x11C8 REG_LPSOFFLOAD_IMR
  [14] BIT_FS_EDCCA_ILDE_TOCNT_INT_EXT_EN — when edcca is low after tbtt, start timer,when timeout for few times(0x180~0x188),set this interrupt 0X11C4[7]
  [13] BIT_FS_HIOE_CHN0_INT_EXT_EN — hioe_chn0 done interrupt 0X11C4[18]
  [12] BIT_FS_HIOE_CHN1_INT_EXT_EN — hioe_chn1 done interrupt 0X11C4[17]
  [9] BIT_LPS_RXBCN_TSF_GT_THRES_INT_EN — The interrupt is issued when difference of tsft in beacon frame of port0 is greater than threshold 0X124[28]
  [8] BIT_LPS_HIOE_CHN_ON_INT_EN — hioe_chn_on done interrupt 0X11C4[16]
  [7] BIT_LPS_HIOE_CHN_OFF_INT_EN — hioe_chn_off done interrupt 0X11C4[15]
  [6] BIT_LPS_TIM_NO_HIT_INT_EN — when no my aid or aid is 0(0x16DC[8]) or my bssid is not in tim element(0x16DB[31]),generate this interrupt 0x11C4[21]
  [5] BIT_LPS_BCNERLY0_INT_EN — This interrupt is issued at the time set by DRVERLYINT register before TBTT0_MB0 time. 0x112C[0]
  [4] BIT_LPS_BCNELY0_AGGR_INT_EN — port 0 Beacon early aggregation interrupt 0x112C[15]
  [3] BIT_LPS_TBTT0_INT_EN — the interrupt from the exact TBTT time for P0 MBSSID0. 0x112C[10]
  [2] BIT_LPS_RX_BCN_P0_INT_EN — When this bit is enable, the interrupt is issued when RX beacon frame occurs in port0. 0x124[21]
  [1] BIT_LPS_RX_BCN_ERR_P0_INT_EN — When this bit is enable, the interrupt is issued when RX beacon frame with fcs error occurs in port0. 0x124[23]
  [0] BIT_LPS_RXBCN_TIMEUP_INT_EN — When this bit is enable, the interrupt is issued when RX beacon frame timeout occurs in port0. 0x124[25]
0x11E0 REG_FT2IMR
  [14] BIT_FS_CTWE_INT2_EN — port2 CTWindow end interrupt for p2p.
  [13] BIT_FS_CTWE_INT_EN0 — port0 CTWindow end interrupt for p2p.
  [12] BIT_FS_CTWE_INT_EN1 — port1 CTWindow end interrupt for p2p.
  [11] BIT_FS_CTWEnd2_INT_EN — CTWindow End NOA2 interrupt.
  [10] BIT_FS_CTWEnd1_INT_EN — CTWindow End NOA1 interrupt.
  [9] BIT_FS_CTWEnd0_INT_EN — CTWindow End NOA0 interrupt.
  [8] BIT_FS_P2P_RFON2_INT_EN — P2P NoA RF on time indication 2 interrupt
  [7] BIT_FS_P2P_RFOFF2_INT_EN — P2P NoA RF off time indication 2 interrupt
  [6] BIT_FS_P2P_RFON1_INT_EN — P2P NoA RF on time indication 1 interrupt
  [5] BIT_FS_P2P_RFOFF1_INT_EN — P2P NoA RF off time indication 1 interrupt
  [4] BIT_FS_P2P_RFON0_INT_EN — P2P NoA RF on time indication 0 interrupt
  [3] BIT_FS_P2P_RFOFF0_INT_EN — P2P NoA RF off time indication 0 interrupt
  [2] BIT_FS_NOA2_TSFT_BIT32_INT_EN — NOA unit2 TSFT bit 32 toggle interrupt
  [1] BIT_FS_NOA1_TSFT_BIT32_INT_EN — NOA unit1 TSFT bit 32 toggle interrupt
  [0] BIT_FS_NOA0_TSF_BIT32_INT_EN — NOA unit0 TSFT bit 32 toggle interrupt
0x11E4 REG_FT2ISR ro
  [14] BIT_FS_CTWE_INT2 — port2 CTWindow end interrupt for p2p.
  [13] BIT_FS_CTWE_INT1 — port1 CTWindow end interrupt for p2p.
  [12] BIT_FS_CTWE_INT0 — port0 CTWindow end interrupt for p2p.
  [11] BIT_FS_CTWEnd2_INT — CTWindow End NOA2 interrupt.
  [10] BIT_FS_CTWEnd1_INT — CTWindow End NOA1 interrupt.
  [9] BIT_FS_CTWEnd0_INT — CTWindow End NOA0 interrupt.
  [8] BIT_FS_P2P_RFON2_INT — P2P NoA RF on time indication 2 interrupt
  [7] BIT_FS_P2P_RFOFF2_INT — P2P NoA RF off time indication 2 interrupt
  [6] BIT_FS_P2P_RFON1_INT — P2P NoA RF on time indication 1 interrupt
  [5] BIT_FS_P2P_RFOFF1_INT — P2P NoA RF off time indication 1 interrupt
  [4] BIT_FS_P2P_RFON0_INT — P2P NoA RF on time indication 0 interrupt
  [3] BIT_FS_P2P_RFOFF0_INT — P2P NoA RF off time indication 0 interrupt
  [2] BIT_FS_NOA2_TSFT_BIT32_INT — NOA unit2 TSFT bit 32 toggle interrupt
  [1] BIT_FS_NOA1_TSFT_BIT32_INT — NOA unit1 TSFT bit 32 toggle interrupt
  [0] BIT_FS_NOA0_TSF_BIT32_INT — NOA unit0 TSFT bit 32 toggle interrupt
{0x11E8+4i} REG_MSG{i} (i=2..5)
  [31:0] BIT_FW_MSG{i} — fw message {i}
